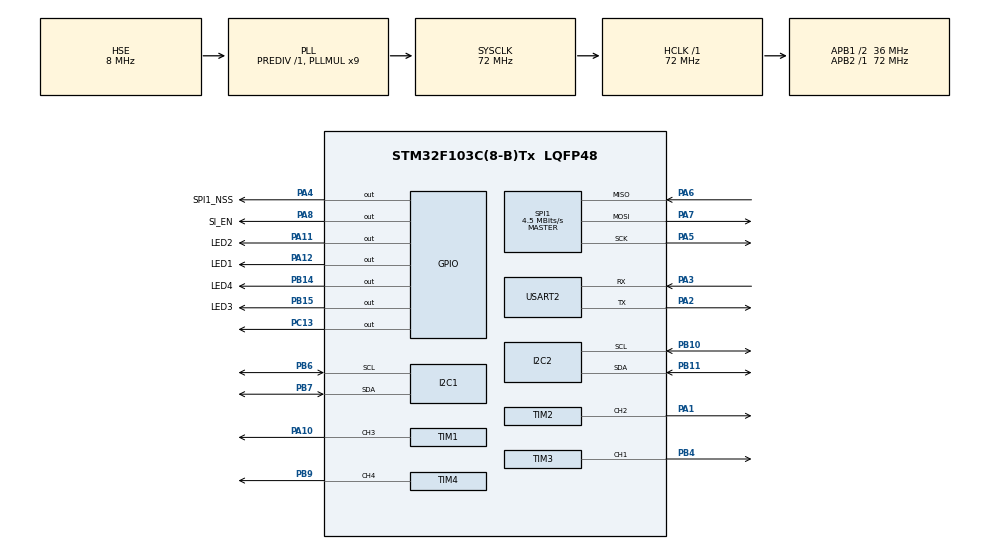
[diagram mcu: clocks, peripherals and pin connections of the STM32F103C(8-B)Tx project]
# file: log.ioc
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Mcu.Family=STM32F1
Mcu.Name=STM32F103C(8-B)Tx
Mcu.Package=LQFP48
NVIC.PriorityGroup=NVIC_PRIORITYGROUP_4
PA1.Signal=S_TIM2_CH2
PA10.Signal=S_TIM1_CH3
PA11.GPIO_Label=LED2
PA11.Signal=GPIO_Output
PA12.GPIO_Label=LED1
PA12.Signal=GPIO_Output
PA13.Mode=Serial_Wire
PA13.Signal=SYS_JTMS-SWDIO
PA14.Mode=Serial_Wire
PA14.Signal=SYS_JTCK-SWCLK
PA2.Mode=Asynchronous
PA2.Signal=USART2_TX
PA3.Mode=Asynchronous
PA3.Signal=USART2_RX
PA4.GPIO_Label=SPI1_NSS
PA4.Signal=GPIO_Output
PA5.Mode=Full_Duplex_Master
PA5.Signal=SPI1_SCK
PA6.Mode=Full_Duplex_Master
PA6.Signal=SPI1_MISO
PA7.Mode=Full_Duplex_Master
PA7.Signal=SPI1_MOSI
PA8.GPIO_Label=SI_EN
PA8.Signal=GPIO_Output
PB10.Mode=I2C
PB10.Signal=I2C2_SCL
PB11.Mode=I2C
PB11.Signal=I2C2_SDA
PB14.GPIO_Label=LED4
PB14.Signal=GPIO_Output
PB15.GPIO_Label=LED3
PB15.Signal=GPIO_Output
PB4.Signal=S_TIM3_CH1
PB6.Mode=I2C
PB6.Signal=I2C1_SCL
PB7.Mode=I2C
PB7.Signal=I2C1_SDA
PB9.Signal=S_TIM4_CH4
PC13-TAMPER-RTC.Signal=GPIO_Output
PD0-OSC_IN.Mode=HSE-External-Oscillator
PD0-OSC_IN.Signal=RCC_OSC_IN
PD1-OSC_OUT.Mode=HSE-External-Oscillator
PD1-OSC_OUT.Signal=RCC_OSC_OUT
ProjectManager.HeapSize=0x200
ProjectManager.StackSize=0x400
ProjectManager.TargetToolchain=CMake
RCC.AHBFreq_Value=72000000
RCC.APB1CLKDivider=RCC_HCLK_DIV2
RCC.APB1Freq_Value=36000000
RCC.APB1TimFreq_Value=72000000
RCC.APB2Freq_Value=72000000
RCC.APB2TimFreq_Value=72000000
RCC.HCLKFreq_Value=72000000
RCC.PLLMUL=RCC_PLL_MUL9
RCC.PLLSourceVirtual=RCC_PLLSOURCE_HSE
RCC.SYSCLKFreq_VALUE=72000000
RCC.SYSCLKSource=RCC_SYSCLKSOURCE_PLLCLK
RCC.USBFreq_Value=72000000
SH.S_TIM1_CH3.0=TIM1_CH3,PWM Generation3 CH3
SH.S_TIM2_CH2.0=TIM2_CH2,PWM Generation2 CH2
SH.S_TIM3_CH1.0=TIM3_CH1,PWM Generation1 CH1
SH.S_TIM4_CH4.0=TIM4_CH4,PWM Generation4 CH4
SPI1.BaudRatePrescaler=SPI_BAUDRATEPRESCALER_16
SPI1.CalculateBaudRate=4.5 MBits/s
SPI1.Direction=SPI_DIRECTION_2LINES
SPI1.Mode=SPI_MODE_MASTER
SPI1.VirtualType=VM_MASTER
TIM1.Channel-PWM\ Generation3\ CH3=TIM_CHANNEL_3
TIM1.Period=2000-1
TIM1.Prescaler=72-1
TIM1.Pulse-PWM\ Generation3\ CH3=2000
TIM2.Channel-PWM\ Generation2\ CH2=TIM_CHANNEL_2
TIM2.Period=2000-1
TIM2.Prescaler=72-1
TIM2.Pulse-PWM\ Generation2\ CH2=1000
TIM3.Channel-PWM\ Generation1\ CH1=TIM_CHANNEL_1
TIM3.Period=2000-1
TIM3.Prescaler=72-1
TIM3.Pulse-PWM\ Generation1\ CH1=1000
TIM4.Channel-PWM\ Generation4\ CH4=TIM_CHANNEL_4
TIM4.Period=2000-1
TIM4.Prescaler=72-1
TIM4.Pulse-PWM\ Generation4\ CH4=2000
USART2.VirtualMode=VM_ASYNC
VP_TIM1_VS_ClockSourceINT.Mode=Internal
VP_TIM2_VS_ClockSourceINT.Mode=Internal
VP_TIM3_VS_ClockSourceINT.Mode=Internal
VP_TIM4_VS_ClockSourceINT.Mode=Internal
board=custom

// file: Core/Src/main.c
/* USER CODE BEGIN Header */
/**
 ******************************************************************************
 * @file           : main.c
 * @brief          : Main program body
 ******************************************************************************
 * @attention
 *
 * Copyright (c) 2026 STMicroelectronics.
 * All rights reserved.
 *
 * This software is licensed under terms that can be found in the LICENSE file
 * in the root directory of this software component.
 * If no LICENSE file comes with this software, it is provided AS-IS.
 *
 ******************************************************************************
 */
/* USER CODE END Header */
#include "main.h"
#include "gpio.h"
#include "i2c.h"
#include "spi.h"
#include "tim.h"
#include "usart.h"

void SystemClock_Config(void);

int main(void) {

  /* MCU Configuration--------------------------------------------------------*/

  /* Reset of all peripherals, Initializes the Flash interface and the Systick.
   */
  HAL_Init();

  /* Configure the system clock */
  SystemClock_Config();

  /* Initialize all configured peripherals */
  MX_GPIO_Init();
  MX_USART2_UART_Init();
  MX_I2C1_Init();
  MX_I2C2_Init();
  MX_SPI1_Init();
  MX_TIM1_Init();
  MX_TIM2_Init();
  MX_TIM3_Init();
  MX_TIM4_Init();
  /* USER CODE BEGIN 2 */
  HAL_TIM_PWM_Start(&htim4, TIM_CHANNEL_4);
  __HAL_TIM_SET_COMPARE(&htim4, TIM_CHANNEL_4, 2000);

  HAL_Delay(3500);
  __HAL_TIM_SET_COMPARE(&htim4, TIM_CHANNEL_4, 1000);
  HAL_Delay(1000);
  // __HAL_TIM_SET_COMPARE(&htim4, TIM_CHANNEL_4, 2000);
  /* USER CODE END 2 */

  /* Infinite loop */
  while (1) {

  }
  /* USER CODE END 3 */
}

void SystemClock_Config(void) {
  RCC_OscInitTypeDef RCC_OscInitStruct = {0};
  RCC_ClkInitTypeDef RCC_ClkInitStruct = {0};

  /** Initializes the RCC Oscillators according to the specified parameters
   * in the RCC_OscInitTypeDef structure.
   */
  RCC_OscInitStruct.OscillatorType = RCC_OSCILLATORTYPE_HSE;
  RCC_OscInitStruct.HSEState = RCC_HSE_ON;
  RCC_OscInitStruct.HSEPredivValue = RCC_HSE_PREDIV_DIV1;
  RCC_OscInitStruct.HSIState = RCC_HSI_ON;
  RCC_OscInitStruct.PLL.PLLState = RCC_PLL_ON;
  RCC_OscInitStruct.PLL.PLLSource = RCC_PLLSOURCE_HSE;
  RCC_OscInitStruct.PLL.PLLMUL = RCC_PLL_MUL9;
  if (HAL_RCC_OscConfig(&RCC_OscInitStruct) != HAL_OK) {
    Error_Handler();
  }

  /** Initializes the CPU, AHB and APB buses clocks
   */
  RCC_ClkInitStruct.ClockType = RCC_CLOCKTYPE_HCLK | RCC_CLOCKTYPE_SYSCLK |
                                RCC_CLOCKTYPE_PCLK1 | RCC_CLOCKTYPE_PCLK2;
  RCC_ClkInitStruct.SYSCLKSource = RCC_SYSCLKSOURCE_PLLCLK;
  RCC_ClkInitStruct.AHBCLKDivider = RCC_SYSCLK_DIV1;
  RCC_ClkInitStruct.APB1CLKDivider = RCC_HCLK_DIV2;
  RCC_ClkInitStruct.APB2CLKDivider = RCC_HCLK_DIV1;

  if (HAL_RCC_ClockConfig(&RCC_ClkInitStruct, FLASH_LATENCY_2) != HAL_OK) {
    Error_Handler();
  }
}

void Error_Handler(void) {
  __disable_irq();
  while (1) {
  }
}
#ifdef USE_FULL_ASSERT
/**
 * @brief  Reports the name of the source file and the source line number
 *         where the assert_param error has occurred.
 * @param  file: pointer to the source file name
 * @param  line: assert_param error line source number
 * @retval None
 */
void assert_failed(uint8_t *file, uint32_t line) {
  /* USER CODE BEGIN 6 */
  /* User can add his own implementation to report the file name and line
     number, ex: printf("Wrong parameters value: file %s on line %d\r\n", file,
     line) */
  /* USER CODE END 6 */
}
#endif /* USE_FULL_ASSERT */
